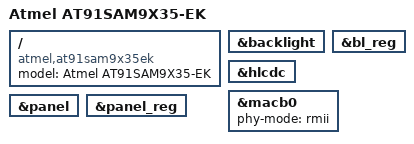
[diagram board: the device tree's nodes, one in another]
// SPDX-License-Identifier: GPL-2.0-or-later
/*
 * at91sam9x35ek.dts - Device Tree file for AT91SAM9X35-EK board
 *
 *  Copyright (C) 2012 Atmel,
 *                2012 Nicolas Ferre <nicolas.ferre@atmel.com>
 */
/dts-v1/;
#include "at91sam9x35.dtsi"
#include "at91sam9x5dm.dtsi"
#include "at91sam9x5ek.dtsi"

/ {
	model = "Atmel AT91SAM9X35-EK";
	compatible = "atmel,at91sam9x35ek", "atmel,at91sam9x5ek", "atmel,at91sam9x5", "atmel,at91sam9";
};

&backlight {
	status = "okay";
};

&bl_reg {
	status = "okay";
};

&hlcdc {
	status = "okay";
};

&macb0 {
	phy-mode = "rmii";
	status = "okay";
};

&panel {
	status = "okay";
};

&panel_reg {
	status = "okay";
};
